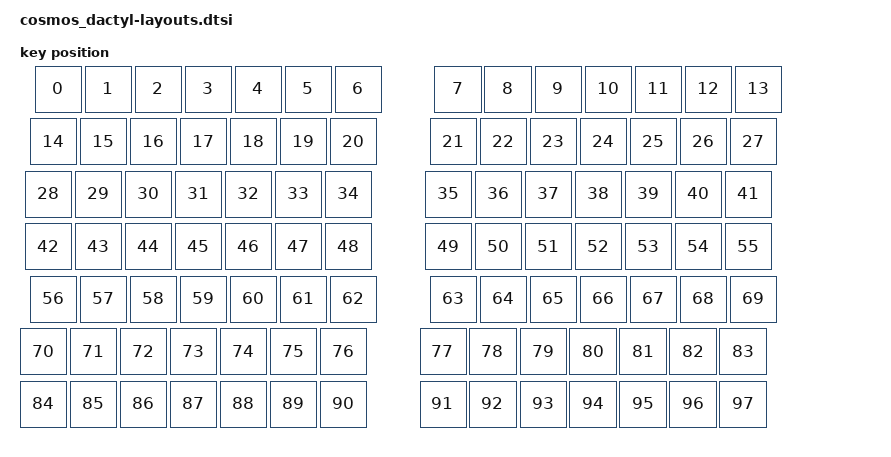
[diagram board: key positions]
#include <physical_layouts.dtsi>

/ {
    physical_layout: physical_layout {
        compatible = "zmk,physical-layout";
        display-name = "Default";
        transform = <&default_transform>;
        kscan = <&kscan0>;
        keys
            = <&key_physical_attrs 100 100    0   0 0 0 0>
            , <&key_physical_attrs 100 100  100   0 0 0 0>
            , <&key_physical_attrs 100 100  200   0 0 0 0>
            , <&key_physical_attrs 100 100  300   0 0 0 0>
            , <&key_physical_attrs 100 100  400   0 0 0 0>
            , <&key_physical_attrs 100 100  500   0 0 0 0>
            , <&key_physical_attrs 100 100  600   0 0 0 0>
            , <&key_physical_attrs 100 100  800   0 0 0 0>
            , <&key_physical_attrs 100 100  900   0 0 0 0>
            , <&key_physical_attrs 100 100 1000   0 0 0 0>
            , <&key_physical_attrs 100 100 1100   0 0 0 0>
            , <&key_physical_attrs 100 100 1200   0 0 0 0>
            , <&key_physical_attrs 100 100 1300   0 0 0 0>
            , <&key_physical_attrs 100 100 1400   0 0 0 0>
            , <&key_physical_attrs 100 100 (-10) 105 0 0 0>
            , <&key_physical_attrs 100 100   90 105 0 0 0>
            , <&key_physical_attrs 100 100  190 105 0 0 0>
            , <&key_physical_attrs 100 100  290 105 0 0 0>
            , <&key_physical_attrs 100 100  390 105 0 0 0>
            , <&key_physical_attrs 100 100  490 105 0 0 0>
            , <&key_physical_attrs 100 100  590 105 0 0 0>
            , <&key_physical_attrs 100 100  790 105 0 0 0>
            , <&key_physical_attrs 100 100  890 105 0 0 0>
            , <&key_physical_attrs 100 100  990 105 0 0 0>
            , <&key_physical_attrs 100 100 1090 105 0 0 0>
            , <&key_physical_attrs 100 100 1190 105 0 0 0>
            , <&key_physical_attrs 100 100 1290 105 0 0 0>
            , <&key_physical_attrs 100 100 1390 105 0 0 0>
            , <&key_physical_attrs 100 100 (-20) 210 0 0 0>
            , <&key_physical_attrs 100 100   80 210 0 0 0>
            , <&key_physical_attrs 100 100  180 210 0 0 0>
            , <&key_physical_attrs 100 100  280 210 0 0 0>
            , <&key_physical_attrs 100 100  380 210 0 0 0>
            , <&key_physical_attrs 100 100  480 210 0 0 0>
            , <&key_physical_attrs 100 100  580 210 0 0 0>
            , <&key_physical_attrs 100 100  780 210 0 0 0>
            , <&key_physical_attrs 100 100  880 210 0 0 0>
            , <&key_physical_attrs 100 100  980 210 0 0 0>
            , <&key_physical_attrs 100 100 1080 210 0 0 0>
            , <&key_physical_attrs 100 100 1180 210 0 0 0>
            , <&key_physical_attrs 100 100 1280 210 0 0 0>
            , <&key_physical_attrs 100 100 1380 210 0 0 0>
            , <&key_physical_attrs 100 100 (-20) 315 0 0 0>
            , <&key_physical_attrs 100 100   80 315 0 0 0>
            , <&key_physical_attrs 100 100  180 315 0 0 0>
            , <&key_physical_attrs 100 100  280 315 0 0 0>
            , <&key_physical_attrs 100 100  380 315 0 0 0>
            , <&key_physical_attrs 100 100  480 315 0 0 0>
            , <&key_physical_attrs 100 100  580 315 0 0 0>
            , <&key_physical_attrs 100 100  780 315 0 0 0>
            , <&key_physical_attrs 100 100  880 315 0 0 0>
            , <&key_physical_attrs 100 100  980 315 0 0 0>
            , <&key_physical_attrs 100 100 1080 315 0 0 0>
            , <&key_physical_attrs 100 100 1180 315 0 0 0>
            , <&key_physical_attrs 100 100 1280 315 0 0 0>
            , <&key_physical_attrs 100 100 1380 315 0 0 0>
            , <&key_physical_attrs 100 100 (-10) 420 0 0 0>
            , <&key_physical_attrs 100 100   90 420 0 0 0>
            , <&key_physical_attrs 100 100  190 420 0 0 0>
            , <&key_physical_attrs 100 100  290 420 0 0 0>
            , <&key_physical_attrs 100 100  390 420 0 0 0>
            , <&key_physical_attrs 100 100  490 420 0 0 0>
            , <&key_physical_attrs 100 100  590 420 0 0 0>
            , <&key_physical_attrs 100 100  790 420 0 0 0>
            , <&key_physical_attrs 100 100  890 420 0 0 0>
            , <&key_physical_attrs 100 100  990 420 0 0 0>
            , <&key_physical_attrs 100 100 1090 420 0 0 0>
            , <&key_physical_attrs 100 100 1190 420 0 0 0>
            , <&key_physical_attrs 100 100 1290 420 0 0 0>
            , <&key_physical_attrs 100 100 1390 420 0 0 0>
            , <&key_physical_attrs 100 100 (-30) 525 0 0 0>
            , <&key_physical_attrs 100 100   70 525 0 0 0>
            , <&key_physical_attrs 100 100  170 525 0 0 0>
            , <&key_physical_attrs 100 100  270 525 0 0 0>
            , <&key_physical_attrs 100 100  370 525 0 0 0>
            , <&key_physical_attrs 100 100  470 525 0 0 0>
            , <&key_physical_attrs 100 100  570 525 0 0 0>
            , <&key_physical_attrs 100 100  770 525 0 0 0>
            , <&key_physical_attrs 100 100  870 525 0 0 0>
            , <&key_physical_attrs 100 100  970 525 0 0 0>
            , <&key_physical_attrs 100 100 1070 525 0 0 0>
            , <&key_physical_attrs 100 100 1170 525 0 0 0>
            , <&key_physical_attrs 100 100 1270 525 0 0 0>
            , <&key_physical_attrs 100 100 1370 525 0 0 0>
            , <&key_physical_attrs 100 100 (-30) 630 0 0 0>
            , <&key_physical_attrs 100 100   70 630 0 0 0>
            , <&key_physical_attrs 100 100  170 630 0 0 0>
            , <&key_physical_attrs 100 100  270 630 0 0 0>
            , <&key_physical_attrs 100 100  370 630 0 0 0>
            , <&key_physical_attrs 100 100  470 630 0 0 0>
            , <&key_physical_attrs 100 100  570 630 0 0 0>
            , <&key_physical_attrs 100 100  770 630 0 0 0>
            , <&key_physical_attrs 100 100  870 630 0 0 0>
            , <&key_physical_attrs 100 100  970 630 0 0 0>
            , <&key_physical_attrs 100 100 1070 630 0 0 0>
            , <&key_physical_attrs 100 100 1170 630 0 0 0>
            , <&key_physical_attrs 100 100 1270 630 0 0 0>
            , <&key_physical_attrs 100 100 1370 630 0 0 0>;
    };
};
